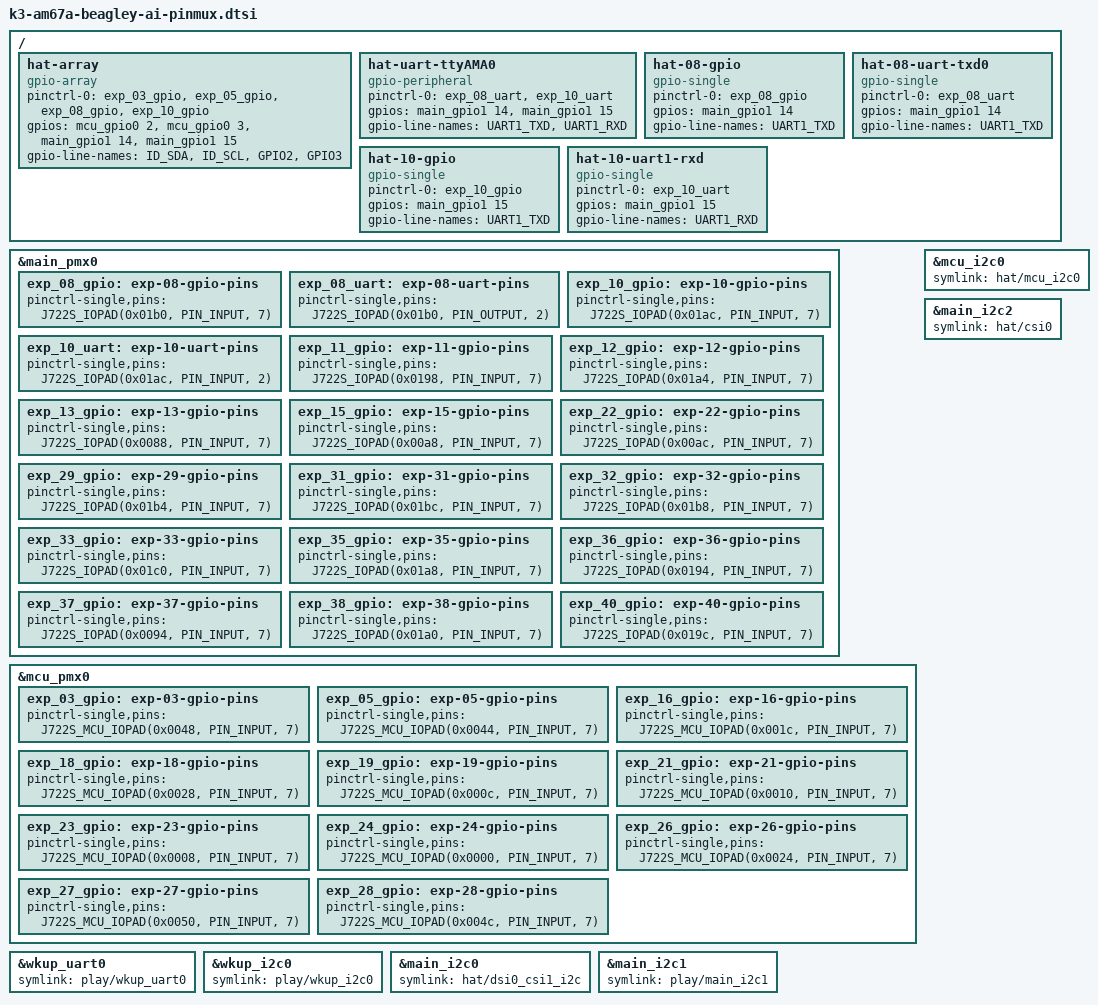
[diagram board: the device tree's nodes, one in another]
// SPDX-License-Identifier: GPL-2.0-only OR MIT
/*
 * https://beagley-ai.org/
 *
 * Copyright (C) 2024 Texas Instruments Incorporated - https://www.ti.com/
 * Copyright (C) 2024 Robert Nelson, BeagleBoard.org Foundation
 */

#include <dt-bindings/gpio/gpio.h>

/ {
	hat-array {
		compatible = "gpio-array";
		pinctrl-names = "default";
		pinctrl-0 = <&exp_03_gpio>, <&exp_05_gpio>, <&exp_08_gpio>, <&exp_10_gpio>;

		gpios = <&mcu_gpio0 2 GPIO_ACTIVE_HIGH>,
				<&mcu_gpio0 3 GPIO_ACTIVE_HIGH>,
				<&main_gpio1 14 GPIO_ACTIVE_HIGH>,
				<&main_gpio1 15 GPIO_ACTIVE_HIGH>;
		gpio-line-names = "ID_SDA", "ID_SCL", "GPIO2", "GPIO3";
	};

	hat-uart-ttyAMA0 {
		compatible = "gpio-peripheral";
		pinctrl-names = "default";
		pinctrl-0 = <&exp_08_uart>, <&exp_10_uart>;

		gpios = <&main_gpio1 14 GPIO_ACTIVE_HIGH>,
				<&main_gpio1 15 GPIO_ACTIVE_HIGH>;
		gpio-line-names = "UART1_TXD", "UART1_RXD";
	};

	hat-08-gpio {
		compatible = "gpio-single";
		pinctrl-names = "default";
		pinctrl-0 = <&exp_08_gpio>;

		gpios = <&main_gpio1 14 GPIO_ACTIVE_HIGH>;
		gpio-line-names = "UART1_TXD";
	};

	hat-08-uart-txd0 {
		compatible = "gpio-single";
		pinctrl-names = "default";
		pinctrl-0 = <&exp_08_uart>;

		gpios = <&main_gpio1 14 GPIO_ACTIVE_HIGH>;
		gpio-line-names = "UART1_TXD";
	};

	hat-10-gpio {
		compatible = "gpio-single";
		pinctrl-names = "default";
		pinctrl-0 = <&exp_10_gpio>;

		gpios = <&main_gpio1 15 GPIO_ACTIVE_HIGH>;
		gpio-line-names = "UART1_TXD";
	};

	hat-10-uart1-rxd {
		compatible = "gpio-single";
		pinctrl-names = "default";
		pinctrl-0 = <&exp_10_uart>;

		gpios = <&main_gpio1 15 GPIO_ACTIVE_HIGH>;
		gpio-line-names = "UART1_RXD";
	};
};

&main_pmx0 {
	exp_08_gpio: exp-08-gpio-pins {
		pinctrl-single,pins = <
			J722S_IOPAD(0x01b0, PIN_INPUT, 7) /* (F24) MCASP0_ACLKR.GPIO1_14 */
		>;
	};

	exp_08_uart: exp-08-uart-pins {
		pinctrl-single,pins = <
			J722S_IOPAD(0x01b0, PIN_OUTPUT, 2) /* (F24) MCASP0_ACLKR.UART1_TXD */
		>;
	};

	exp_10_gpio: exp-10-gpio-pins {
		pinctrl-single,pins = <
			J722S_IOPAD(0x01ac, PIN_INPUT, 7) /* (C27) MCASP0_AFSR.GPIO1_13 */
		>;
	};

	exp_10_uart: exp-10-uart-pins {
		pinctrl-single,pins = <
			J722S_IOPAD(0x01ac, PIN_INPUT, 2) /* (C27) MCASP0_AFSR.UART1_RXD */
		>;
	};

	exp_11_gpio: exp-11-gpio-pins {
		pinctrl-single,pins = <
			J722S_IOPAD(0x0198, PIN_INPUT, 7) /* (A26) MCASP0_AXR2.GPIO1_8 */
		>;
	};

	exp_12_gpio: exp-12-gpio-pins {
		pinctrl-single,pins = <
			J722S_IOPAD(0x01a4, PIN_INPUT, 7) /* (D25) MCASP0_ACLKX.GPIO1_11 */
		>;
	};

	exp_13_gpio: exp-13-gpio-pins {
		pinctrl-single,pins = <
			J722S_IOPAD(0x0088, PIN_INPUT, 7) /* (N22) GPMC0_OEn_REn.GPIO0_33 */
		>;
	};

	exp_15_gpio: exp-15-gpio-pins {
		pinctrl-single,pins = <
			J722S_IOPAD(0x00a8, PIN_INPUT, 7) /* (R27) GPMC0_CSn0.GPIO0_41 */
		>;
	};

	exp_22_gpio: exp-22-gpio-pins {
		pinctrl-single,pins = <
			J722S_IOPAD(0x00ac, PIN_INPUT, 7) /* (P21) GPMC0_CSn1.GPIO0_42 */
		>;
	};

	exp_29_gpio: exp-29-gpio-pins {
		pinctrl-single,pins = <
			J722S_IOPAD(0x01b4, PIN_INPUT, 7) /* (B20) SPI0_CS0.GPIO1_15 */
		>;
	};

	exp_31_gpio: exp-31-gpio-pins {
		pinctrl-single,pins = <
			J722S_IOPAD(0x01bc, PIN_INPUT, 7) /* (D20) SPI0_CLK.GPIO1_17 */
		>;
	};

	exp_32_gpio: exp-32-gpio-pins {
		pinctrl-single,pins = <
			J722S_IOPAD(0x01b8, PIN_INPUT, 7) /* (C20) SPI0_CS1.GPIO1_16 */
		>;
	};

	exp_33_gpio: exp-33-gpio-pins {
		pinctrl-single,pins = <
			J722S_IOPAD(0x01c0, PIN_INPUT, 7) /* (E19) SPI0_D0.GPIO1_18 */
		>;
	};

	exp_35_gpio: exp-35-gpio-pins {
		pinctrl-single,pins = <
			J722S_IOPAD(0x01a8, PIN_INPUT, 7) /* (C26) MCASP0_AFSX.GPIO1_12 */
		>;
	};

	exp_36_gpio: exp-36-gpio-pins {
		pinctrl-single,pins = <
			J722S_IOPAD(0x0194, PIN_INPUT, 7) /* (A25) MCASP0_AXR3.GPIO1_7 */
		>;
	};

	exp_37_gpio: exp-37-gpio-pins {
		pinctrl-single,pins = <
			J722S_IOPAD(0x0094, PIN_INPUT, 7) /* (P26) GPMC0_BE1n.GPIO0_36 */
		>;
	};

	exp_38_gpio: exp-38-gpio-pins {
		pinctrl-single,pins = <
			J722S_IOPAD(0x01a0, PIN_INPUT, 7) /* (F23) MCASP0_AXR0.GPIO1_10 */
		>;
	};

	exp_40_gpio: exp-40-gpio-pins {
		pinctrl-single,pins = <
			J722S_IOPAD(0x019c, PIN_INPUT, 7) /* (B25) MCASP0_AXR1.GPIO1_9 */
		>;
	};
};

&mcu_pmx0 {
	exp_03_gpio: exp-03-gpio-pins {
		pinctrl-single,pins = <
			J722S_MCU_IOPAD(0x0048, PIN_INPUT, 7) /* (E11) MCU_I2C0_SDA.MCU_GPIO0_18 */
		>;
	};

	exp_05_gpio: exp-05-gpio-pins {
		pinctrl-single,pins = <
			J722S_MCU_IOPAD(0x0044, PIN_INPUT, 7) /* (B13) MCU_I2C0_SCL.MCU_GPIO0_17 */
		>;
	};

	exp_16_gpio: exp-16-gpio-pins {
		pinctrl-single,pins = <
			J722S_MCU_IOPAD(0x001c, PIN_INPUT, 7) /* (B5) MCU_UART0_CTSn.MCU_GPIO0_7 */
		>;
	};

	exp_18_gpio: exp-18-gpio-pins {
		pinctrl-single,pins = <
			J722S_MCU_IOPAD(0x0028, PIN_INPUT, 7) /* (C8) WKUP_UART0_TXD.MCU_GPIO0_10 */
		>;
	};

	exp_19_gpio: exp-19-gpio-pins {
		pinctrl-single,pins = <
			J722S_MCU_IOPAD(0x000c, PIN_INPUT, 7) /* (B12) MCU_SPI0_D0.MCU_GPIO0_3 */
		>;
	};

	exp_21_gpio: exp-21-gpio-pins {
		pinctrl-single,pins = <
			J722S_MCU_IOPAD(0x0010, PIN_INPUT, 7) /* (C11) MCU_SPI0_D1.MCU_GPIO0_4 */
		>;
	};

	exp_23_gpio: exp-23-gpio-pins {
		pinctrl-single,pins = <
			J722S_MCU_IOPAD(0x0008, PIN_INPUT, 7) /* (A9) MCU_SPI0_CLK.MCU_GPIO0_2 */
		>;
	};

	exp_24_gpio: exp-24-gpio-pins {
		pinctrl-single,pins = <
			J722S_MCU_IOPAD(0x0000, PIN_INPUT, 7) /* (C12) MCU_SPI0_CS0.MCU_GPIO0_0 */
		>;
	};

	exp_26_gpio: exp-26-gpio-pins {
		pinctrl-single,pins = <
			J722S_MCU_IOPAD(0x0024, PIN_INPUT, 7) /* (B3) WKUP_UART0_RXD.MCU_GPIO0_9 */
		>;
	};

	exp_27_gpio: exp-27-gpio-pins {
		pinctrl-single,pins = <
			J722S_MCU_IOPAD(0x0050, PIN_INPUT, 7) /* (D11) WKUP_I2C0_SDA.MCU_GPIO0_20 */
		>;
	};

	exp_28_gpio: exp-28-gpio-pins {
		pinctrl-single,pins = <
			J722S_MCU_IOPAD(0x004c, PIN_INPUT, 7) /* (B9) WKUP_I2C0_SCL.MCU_GPIO0_19 */
		>;
	};
};

&mcu_i2c0 {
	symlink = "hat/mcu_i2c0";
};

&wkup_uart0 {
	symlink = "play/wkup_uart0";
};

&wkup_i2c0 {
	symlink = "play/wkup_i2c0";
};

dsi0_csi1_i2c: &main_i2c0 {
	symlink = "hat/dsi0_csi1_i2c";
};

&main_i2c1 {
	symlink = "play/main_i2c1";
};

csi0_i2c: &main_i2c2 {
	symlink = "hat/csi0";
};
